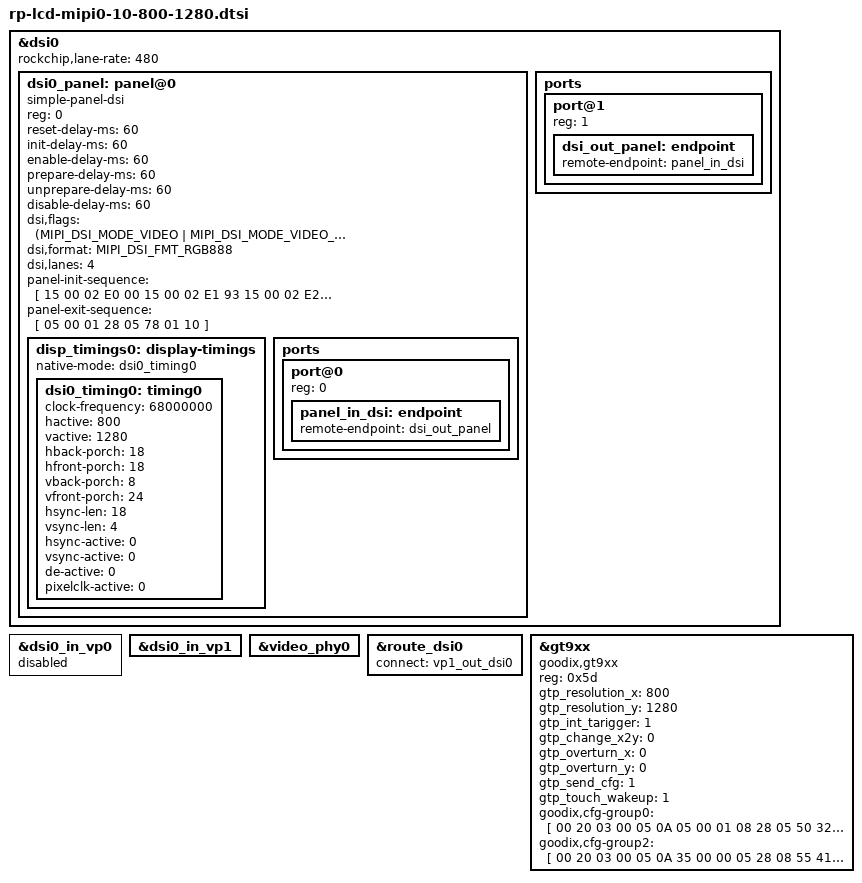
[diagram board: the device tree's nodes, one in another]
#include "rp-lcd-hdmi.dtsi"
#define RP_SINGLE_LCD





&dsi0 {
	status = "okay";
	rockchip,lane-rate = <480>;
	dsi0_panel: panel@0 {
		status = "okay";
		compatible = "simple-panel-dsi";
		reg = <0>;
		reset-delay-ms = <60>;
		init-delay-ms = <60>;
		enable-delay-ms = <60>;
		prepare-delay-ms = <60>;
		unprepare-delay-ms = <60>;
		disable-delay-ms = <60>;
		dsi,flags = <(MIPI_DSI_MODE_VIDEO | MIPI_DSI_MODE_VIDEO_BURST |
			MIPI_DSI_MODE_LPM | MIPI_DSI_MODE_EOT_PACKET)>;
		dsi,format = <MIPI_DSI_FMT_RGB888>;
		dsi,lanes  = <4>;
		
		/**
		 * power-supply = <>;
		 * reset-gpios = <>;
		 *
		 * lcd reset pin and power supply
		 * please refer to ***-lcd-gpio.dtsi
		 * that included in main dts.
		 */
		
		panel-init-sequence = [
			15 00 02 E0 00
			15 00 02 E1 93
			15 00 02 E2 65
			15 00 02 E3 F8
			15 00 02 E0 04
			15 00 02 2D 03
			15 00 02 E0 00
			15 00 02 80 03
			15 00 02 70 02
			15 00 02 71 23
			15 00 02 72 06
			15 00 02 E0 01
			15 00 02 00 00
			15 00 02 01 66
			15 00 02 03 00
			15 00 02 04 6D
			15 00 02 17 00
			15 00 02 18 BF
			15 00 02 19 00
			15 00 02 1A 00
			15 00 02 1B BF
			15 00 02 1C 00
			15 00 02 1F 3E
			15 00 02 20 28
			15 00 02 21 28
			15 00 02 22 0E
			15 00 02 37 09
			15 00 02 38 04
			15 00 02 39 08
			15 00 02 3A 12
			15 00 02 3C 78
			15 00 02 3D FF
			15 00 02 3E FF
			15 00 02 3F 7F
			15 00 02 40 06
			15 00 02 41 A0
			15 00 02 55 0F
			15 00 02 56 01
			15 00 02 57 69
			15 00 02 58 0A
			15 00 02 59 0A
			15 00 02 5A 29
			15 00 02 5B 15
			15 00 02 5D 7C
			15 00 02 5E 65
			15 00 02 5F 55
			15 00 02 60 49
			15 00 02 61 44
			15 00 02 62 35
			15 00 02 63 3A
			15 00 02 64 23
			15 00 02 65 3D
			15 00 02 66 3C
			15 00 02 67 3D
			15 00 02 68 5D
			15 00 02 69 4D
			15 00 02 6A 56
			15 00 02 6B 48
			15 00 02 6C 45
			15 00 02 6D 38
			15 00 02 6E 25
			15 00 02 6F 00
			15 00 02 70 7C
			15 00 02 71 65
			15 00 02 72 55
			15 00 02 73 49
			15 00 02 74 44
			15 00 02 75 35
			15 00 02 76 3A
			15 00 02 77 23
			15 00 02 78 3D
			15 00 02 79 3C
			15 00 02 7A 3D
			15 00 02 7B 5D
			15 00 02 7C 4D
			15 00 02 7D 56
			15 00 02 7E 48
			15 00 02 7F 45
			15 00 02 80 38
			15 00 02 81 25
			15 00 02 82 00
			15 00 02 E0 02
			15 00 02 00 1E
			15 00 02 01 1E
			15 00 02 02 41
			15 00 02 03 41
			15 00 02 04 43
			15 00 02 05 43
			15 00 02 06 1F
			15 00 02 07 1F
			15 00 02 08 1F
			15 00 02 09 1F
			15 00 02 0A 1E
			15 00 02 0B 1E
			15 00 02 0C 1F
			15 00 02 0D 47
			15 00 02 0E 47
			15 00 02 0F 45
			15 00 02 10 45
			15 00 02 11 4B
			15 00 02 12 4B
			15 00 02 13 49
			15 00 02 14 49
			15 00 02 15 1F
			15 00 02 16 1E
			15 00 02 17 1E
			15 00 02 18 40
			15 00 02 19 40
			15 00 02 1A 42
			15 00 02 1B 42
			15 00 02 1C 1F
			15 00 02 1D 1F
			15 00 02 1E 1F
			15 00 02 1F 1f
			15 00 02 20 1E
			15 00 02 21 1E
			15 00 02 22 1f
			15 00 02 23 46
			15 00 02 24 46
			15 00 02 25 44
			15 00 02 26 44
			15 00 02 27 4A
			15 00 02 28 4A
			15 00 02 29 48
			15 00 02 2A 48
			15 00 02 2B 1f
			15 00 02 2C 1F
			15 00 02 2D 1F
			15 00 02 2E 42
			15 00 02 2F 42
			15 00 02 30 40
			15 00 02 31 40
			15 00 02 32 1E
			15 00 02 33 1E
			15 00 02 34 1F
			15 00 02 35 1F
			15 00 02 36 1E
			15 00 02 37 1E
			15 00 02 38 1F
			15 00 02 39 48
			15 00 02 3A 48
			15 00 02 3B 4A
			15 00 02 3C 4A
			15 00 02 3D 44
			15 00 02 3E 44
			15 00 02 3F 46
			15 00 02 40 46
			15 00 02 41 1F
			15 00 02 42 1F
			15 00 02 43 1F
			15 00 02 44 43
			15 00 02 45 43
			15 00 02 46 41
			15 00 02 47 41
			15 00 02 48 1E
			15 00 02 49 1E
			15 00 02 4A 1E
			15 00 02 4B 1F
			15 00 02 4C 1E
			15 00 02 4D 1E
			15 00 02 4E 1F
			15 00 02 4F 49
			15 00 02 50 49
			15 00 02 51 4B
			15 00 02 52 4B
			15 00 02 53 45
			15 00 02 54 45
			15 00 02 55 47
			15 00 02 56 47
			15 00 02 57 1F
			15 00 02 58 10
			15 00 02 59 00
			15 00 02 5A 00
			15 00 02 5B 30
			15 00 02 5C 02
			15 00 02 5D 40
			15 00 02 5E 01
			15 00 02 5F 02
			15 00 02 60 30
			15 00 02 61 01
			15 00 02 62 02
			15 00 02 63 6A
			15 00 02 64 6A
			15 00 02 65 05
			15 00 02 66 12
			15 00 02 67 74
			15 00 02 68 04
			15 00 02 69 6A
			15 00 02 6A 6A
			15 00 02 6B 08
			15 00 02 6C 00
			15 00 02 6D 06
			15 00 02 6E 00
			15 00 02 6F 88
			15 00 02 70 00
			15 00 02 71 00
			15 00 02 72 06
			15 00 02 73 7B
			15 00 02 74 00
			15 00 02 75 07
			15 00 02 76 00
			15 00 02 77 5D
			15 00 02 78 17
			15 00 02 79 1F
			15 00 02 7A 00
			15 00 02 7B 00
			15 00 02 7C 00
			15 00 02 7D 03
			15 00 02 7E 7B
			15 00 02 E0 04
			15 00 02 2B 2B
			15 00 02 2E 44
			15 00 02 E0 01
			15 00 02 0E 01
			15 00 02 E0 03
			15 00 02 98 2F
			15 00 02 E0 00
			15 00 02 E6 02
			15 00 02 E7 02

                        05 78 01 11
                        05 05 01 29
                        15 0a 02 35 00
		];
		
		panel-exit-sequence = [
			05 00 01 28
			05 78 01 10
		];

		disp_timings0: display-timings {
			native-mode = <&dsi0_timing0>;
			dsi0_timing0: timing0 {
                                clock-frequency = <68000000>;
                                hactive = <800>;
                                vactive = <1280>;
                                hback-porch = <18>;
                                hfront-porch = <18>;
                                vback-porch = <8>;
                                vfront-porch = <24>;
                                hsync-len = <18>;
                                vsync-len = <4>;
                                hsync-active = <0>;
                                vsync-active = <0>;
                                de-active = <0>;
                                pixelclk-active = <0>;
			};
		};

		ports {
			#address-cells = <1>;
			#size-cells = <0>;

			port@0 {
				reg = <0>;
				panel_in_dsi: endpoint {
					remote-endpoint = <&dsi_out_panel>;
				};
			};
		};
	};

	ports {
		#address-cells = <1>;
		#size-cells = <0>;

		port@1 {
			reg = <1>;
			dsi_out_panel: endpoint {
				remote-endpoint = <&panel_in_dsi>;
			};
		};
	};

};



&dsi0_in_vp0 {
	status = "disabled";
};

&dsi0_in_vp1 {
	status = "okay";
};

&video_phy0 {
	status = "okay";
};


&route_dsi0 {
	status = "okay";
	connect = <&vp1_out_dsi0>;
};



&gt9xx {
	status = "okay";
	compatible = "goodix,gt9xx";
	reg = <0x5d>;
	gtp_resolution_x = <800>;
	gtp_resolution_y = <1280>;
	gtp_int_tarigger = <1>;
	gtp_change_x2y = <0>;
	gtp_overturn_x = <0>;
	gtp_overturn_y = <0>;
	gtp_send_cfg = <1>;
	gtp_touch_wakeup = <1>;

	/**
	 * goodix_rst_gpio = <>;
	 * goodix_irq_gpio = <>;
	 *
	 * touch panel interrupt and reset pin
	 * please refer to ***-lcd-gpio.dtsi
	 * that included in main dts.
	 */

	/* old touchscreen sensor_id0 */
	goodix,cfg-group0 = [
				00 20 03 00 05 0A 05 00 01 08 
				28 05 50 32 03 05 00 00 00 00 
				00 00 00 00 00 00 00 90 30 AA 
				17 15 31 0D 00 00 01 B9 04 25 
				00 00 00 00 00 00 00 00 00 00 
				00 0F 23 94 C5 02 07 00 00 04 
				9F 10 00 8B 13 00 7C 16 00 6B 
				1B 00 60 20 00 60 00 00 00 00 
				00 00 00 00 00 00 00 00 00 00 
				00 00 00 00 00 00 00 00 00 00 
				00 00 00 00 00 00 00 00 00 00 
				00 00 19 18 17 16 15 14 11 10 
				0F 0E 0D 0C 09 08 07 06 05 04 
				01 00 00 00 00 00 00 00 00 00 
				00 00 2A 29 28 27 26 25 24 23 
				22 21 20 1F 1E 1C 1B 19 00 02 
				04 06 07 08 0A 0C 0D 0E 0F 10 
				11 12 13 14 00 00 00 00 00 00 
				00 00 00 00 96 01
				];
	/* new touchscreen sensor_id2 */					
	goodix,cfg-group2 = [
				 00 20 03 00 05 0A 35 00 00
				 05 28 08 55 41 03 05 00 00
				 00 00 00 00 00 1A 1C 1E 14
				 8E 2E 99 14 16 D3 07 00 00
				 00 9B 02 2D 00 00 00 00 00
				 00 00 00 00 00 00 0F 23 94
				 D5 02 07 00 00 04 9D 10 00
				 86 13 00 75 16 00 61 1B 00
				 53 20 00 53 00 00 00 00 00
				 00 00 00 00 00 00 00 00 00
				 00 00 00 00 00 00 00 00 00
				 00 00 00 00 00 00 00 00 00
				 00 00 00 00 17 16 15 14 11
				 10 0F 0E 0D 0C 09 08 07 06
				 05 04 01 00 FF FF 00 00 00
				 00 00 00 00 00 00 00 00 02
				 04 06 07 08 0A 0C 0D 0F 10
				 11 12 13 28 27 26 25 24 23
				 22 21 20 1F 1E 1C 1B 19 FF
				 FF FF FF 00 00 00 00 00 00
				 00 00 00 00 4D 01
			 ];
};



